# iorx74m register map
Registers are 32-bit, access not given, no defined reset value unless marked. A register's access mark holds for its fields unless they carry their own. Addresses are absolute; registers are grouped by the start of their names; [hi:lo] are bit positions; {n}, {i} and the like mark numbered series.

## SFR (part 1 of 10)
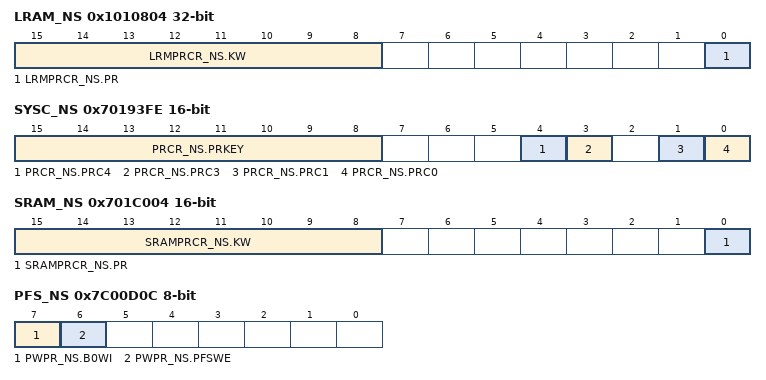
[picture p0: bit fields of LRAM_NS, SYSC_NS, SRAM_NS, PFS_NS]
0x1010804 LRAM_NS
  [15:8] LRMPRCR_NS.KW, [0] LRMPRCR_NS.PR
0x70193FE SYSC_NS 16-bit
  [15:8] PRCR_NS.PRKEY, [4] PRCR_NS.PRC4, [3] PRCR_NS.PRC3, [1] PRCR_NS.PRC1, [0] PRCR_NS.PRC0
0x701C004 SRAM_NS 16-bit
  [15:8] SRAMPRCR_NS.KW, [0] SRAMPRCR_NS.PR
0x7C00D0C PFS_NS 8-bit
  [7] PWPR_NS.B0WI, [6] PWPR_NS.PFSWE
0x81000400 SAU
  [0] AAS.NS
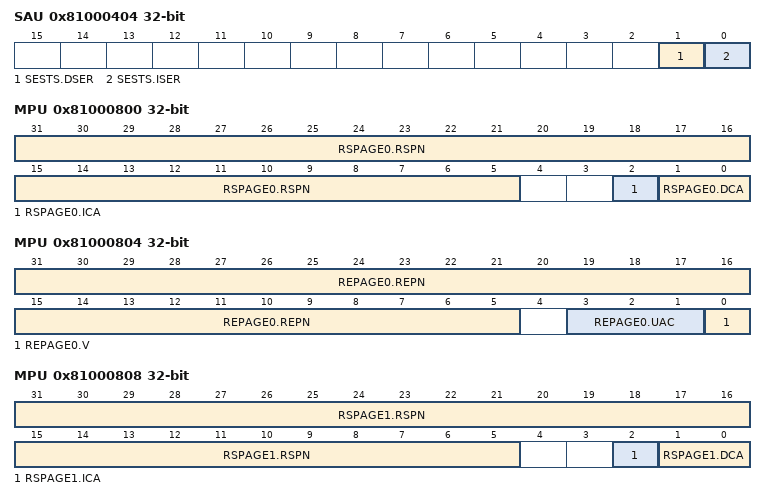
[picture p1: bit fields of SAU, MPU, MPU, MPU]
0x81000404 SAU
  [1] SESTS.DSER, [0] SESTS.ISER
0x81000408 SAU
  [0] SECLR.CLR
0x8100040C SAU
  [31:0] SEA.SEA
0x81000800 MPU
  [31:5] RSPAGE0.RSPN, [2] RSPAGE0.ICA, [1:0] RSPAGE0.DCA
0x81000804 MPU
  [31:5] REPAGE0.REPN, [3:1] REPAGE0.UAC, [0] REPAGE0.V
0x81000808 MPU
  [31:5] RSPAGE1.RSPN, [2] RSPAGE1.ICA, [1:0] RSPAGE1.DCA
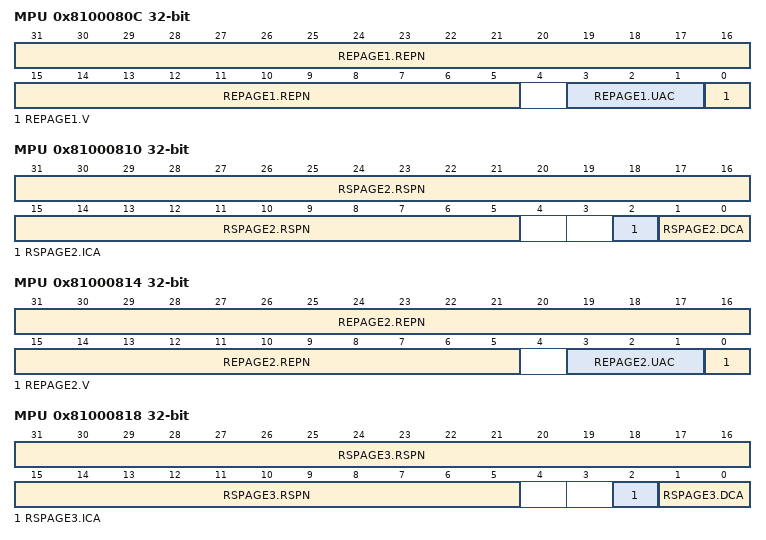
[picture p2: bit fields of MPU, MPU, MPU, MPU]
0x8100080C MPU
  [31:5] REPAGE1.REPN, [3:1] REPAGE1.UAC, [0] REPAGE1.V
0x81000810 MPU
  [31:5] RSPAGE2.RSPN, [2] RSPAGE2.ICA, [1:0] RSPAGE2.DCA
0x81000814 MPU
  [31:5] REPAGE2.REPN, [3:1] REPAGE2.UAC, [0] REPAGE2.V
0x81000818 MPU
  [31:5] RSPAGE3.RSPN, [2] RSPAGE3.ICA, [1:0] RSPAGE3.DCA
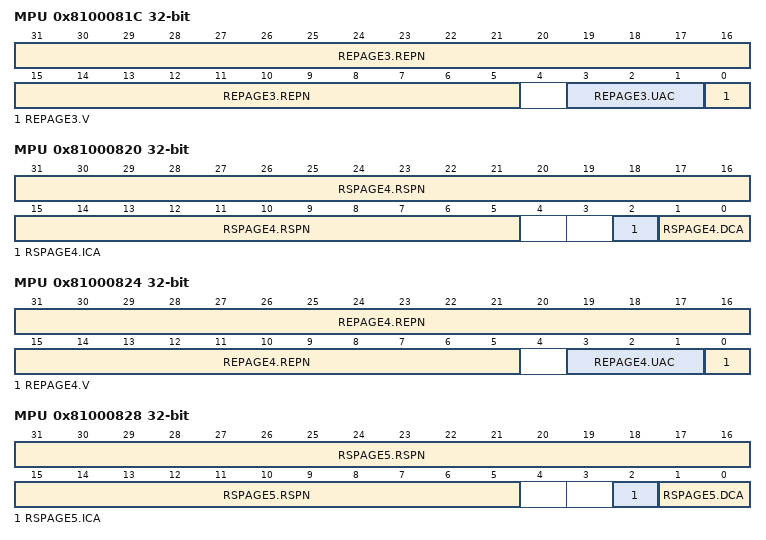
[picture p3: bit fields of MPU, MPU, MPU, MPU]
0x8100081C MPU
  [31:5] REPAGE3.REPN, [3:1] REPAGE3.UAC, [0] REPAGE3.V
0x81000820 MPU
  [31:5] RSPAGE4.RSPN, [2] RSPAGE4.ICA, [1:0] RSPAGE4.DCA
0x81000824 MPU
  [31:5] REPAGE4.REPN, [3:1] REPAGE4.UAC, [0] REPAGE4.V
0x81000828 MPU
  [31:5] RSPAGE5.RSPN, [2] RSPAGE5.ICA, [1:0] RSPAGE5.DCA
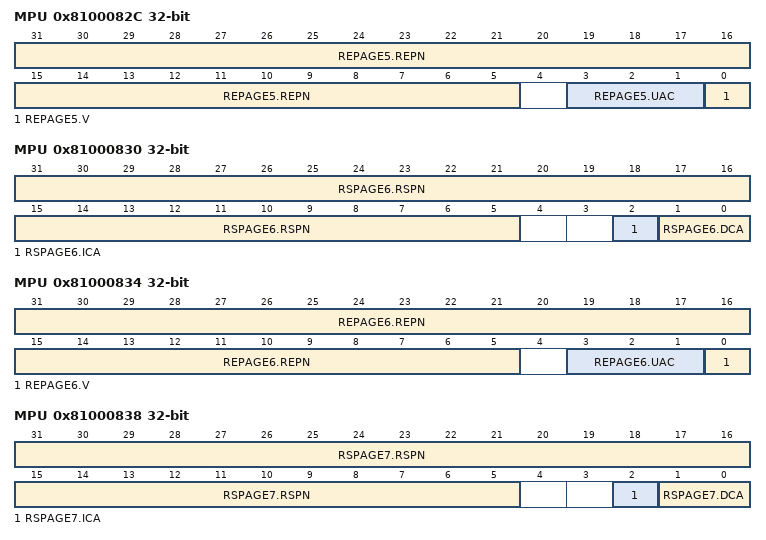
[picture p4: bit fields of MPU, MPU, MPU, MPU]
0x8100082C MPU
  [31:5] REPAGE5.REPN, [3:1] REPAGE5.UAC, [0] REPAGE5.V
0x81000830 MPU
  [31:5] RSPAGE6.RSPN, [2] RSPAGE6.ICA, [1:0] RSPAGE6.DCA
0x81000834 MPU
  [31:5] REPAGE6.REPN, [3:1] REPAGE6.UAC, [0] REPAGE6.V
0x81000838 MPU
  [31:5] RSPAGE7.RSPN, [2] RSPAGE7.ICA, [1:0] RSPAGE7.DCA
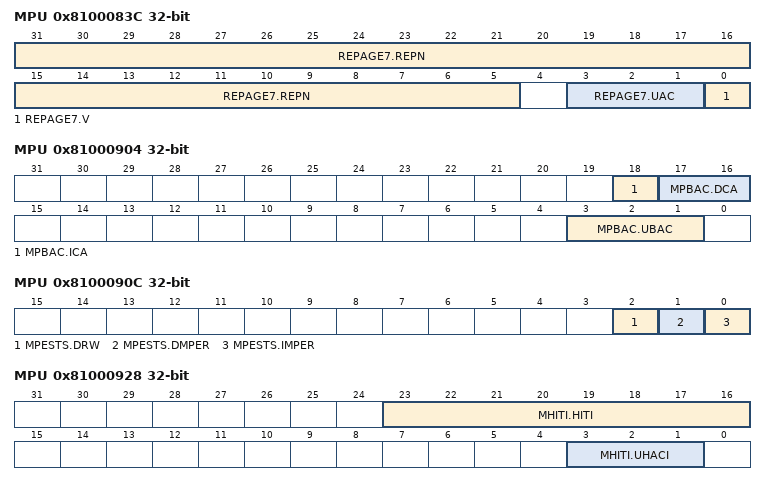
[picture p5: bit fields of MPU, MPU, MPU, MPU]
0x8100083C MPU
  [31:5] REPAGE7.REPN, [3:1] REPAGE7.UAC, [0] REPAGE7.V
0x81000900 MPU
  [0] MPEN.MPEN
0x81000904 MPU
  [18] MPBAC.ICA, [17:16] MPBAC.DCA, [3:1] MPBAC.UBAC
0x81000908 MPU
  [0] MPECLR.CLR
0x8100090C MPU
  [2] MPESTS.DRW, [1] MPESTS.DMPER, [0] MPESTS.IMPER
0x81000914 MPU
  [31:0] MPDEA.DEA
0x81000920 MPU
  [31:0] MPSA.SA
0x81000924 MPU 16-bit
  [0] MPOPS.S
0x81000926 MPU 16-bit
  [0] MPOPI.INV
0x81000928 MPU
  [23:16] MHITI.HITI, [3:1] MHITI.UHACI
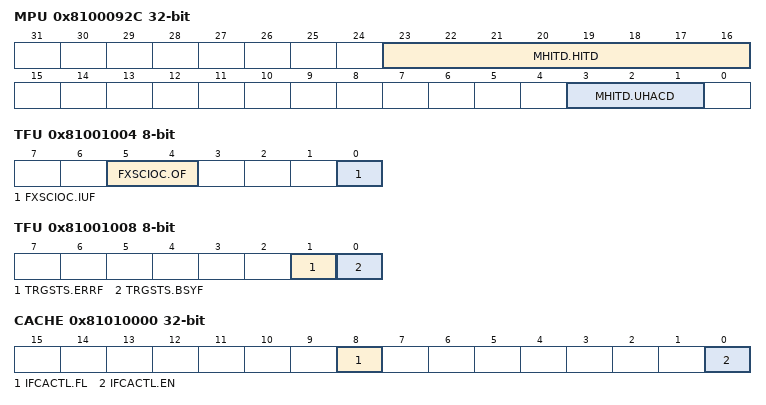
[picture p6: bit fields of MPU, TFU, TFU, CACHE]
0x8100092C MPU
  [23:16] MHITD.HITD, [3:1] MHITD.UHACD
0x81001004 TFU 8-bit
  [5:4] FXSCIOC.OF, [0] FXSCIOC.IUF
0x81001005 TFU 8-bit
  [4] FXATIOC.OUF
0x81001008 TFU 8-bit
  [1] TRGSTS.ERRF, [0] TRGSTS.BSYF
0x81010000 CACHE
  [8] IFCACTL.FL, [0] IFCACTL.EN
0x81010004 CACHE
  [0] IFCAFCT.FL
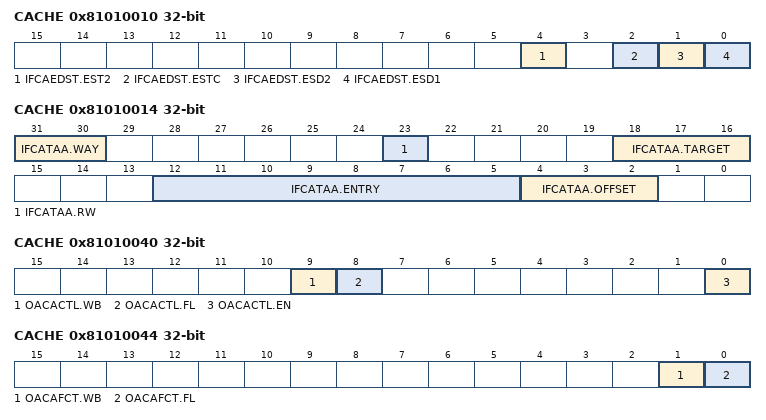
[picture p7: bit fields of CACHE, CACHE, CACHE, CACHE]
0x81010010 CACHE
  [4] IFCAEDST.EST2, [2] IFCAEDST.ESTC, [1] IFCAEDST.ESD2, [0] IFCAEDST.ESD1
0x81010014 CACHE
  [31:30] IFCATAA.WAY, [23] IFCATAA.RW, [18:16] IFCATAA.TARGET, [12:5] IFCATAA.ENTRY, [4:2] IFCATAA.OFFSET
0x81010018 CACHE
  [31:13] IFCATAD_TAG.TAG, [1] IFCATAD_TAG.V, [31:0] IFCATAD_DATA.DATA, [6:0] IFCATAD_ECC.ECC, [4:0] IFCATAD_LRU.LRU, [6:0] IFCATAD_TAGECC.TAGECC
0x81010040 CACHE
  [9] OACACTL.WB, [8] OACACTL.FL, [0] OACACTL.EN
0x81010044 CACHE
  [1] OACAFCT.WB, [0] OACAFCT.FL
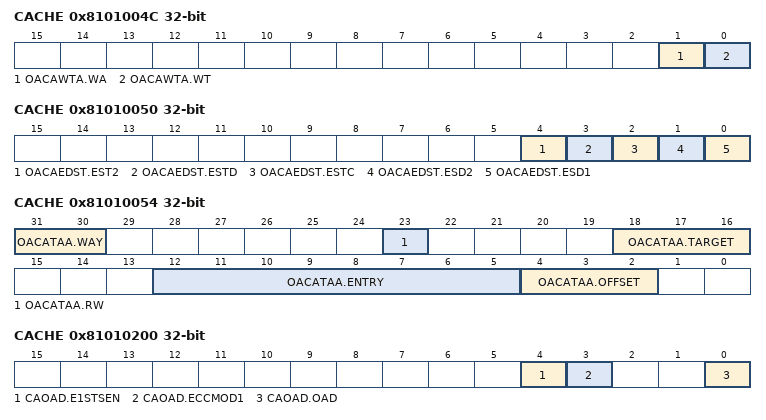
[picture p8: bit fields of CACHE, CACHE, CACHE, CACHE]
0x8101004C CACHE
  [1] OACAWTA.WA, [0] OACAWTA.WT
0x81010050 CACHE
  [4] OACAEDST.EST2, [3] OACAEDST.ESTD, [2] OACAEDST.ESTC, [1] OACAEDST.ESD2, [0] OACAEDST.ESD1
0x81010054 CACHE
  [31:30] OACATAA.WAY, [23] OACATAA.RW, [18:16] OACATAA.TARGET, [12:5] OACATAA.ENTRY, [4:2] OACATAA.OFFSET
0x81010058 CACHE
  [31:13] OACATAD_TAG.TAG, [1] OACATAD_TAG.V, [31:0] OACATAD_DATA.DATA, [6:0] OACATAD_ECC.ECC, [4:0] OACATAD_LRU.LRU, [0] OACATAD_TAG.D, [6:0] OACATAD_TAGECC.TAGECC
0x81010200 CACHE
  [4] CAOAD.E1STSEN, [3] CAOAD.ECCMOD1, [0] CAOAD.OAD
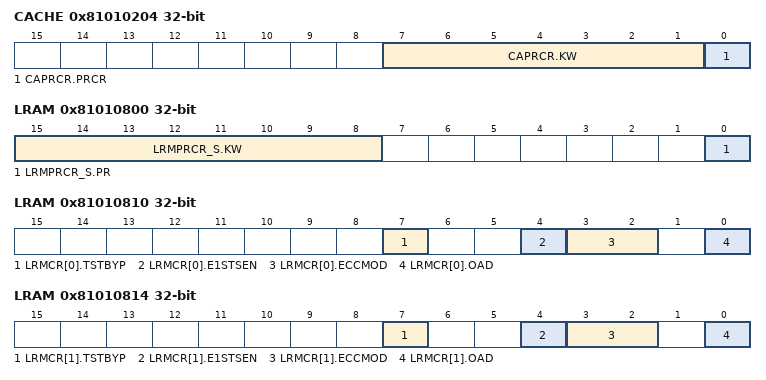
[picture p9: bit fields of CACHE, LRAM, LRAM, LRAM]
0x81010204 CACHE
  [7:1] CAPRCR.KW, [0] CAPRCR.PRCR
0x81010800 LRAM
  [15:8] LRMPRCR_S.KW, [0] LRMPRCR_S.PR
0x81010810 LRAM
  [7] LRMCR[0].TSTBYP, [4] LRMCR[0].E1STSEN, [3:2] LRMCR[0].ECCMOD, [0] LRMCR[0].OAD
0x81010814 LRAM
  [7] LRMCR[1].TSTBYP, [4] LRMCR[1].E1STSEN, [3:2] LRMCR[1].ECCMOD, [0] LRMCR[1].OAD
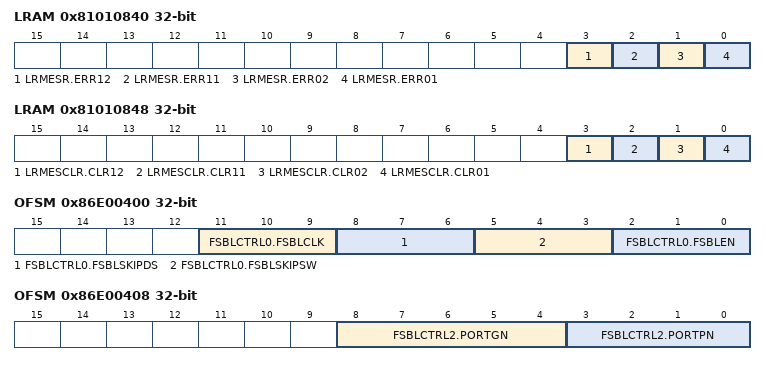
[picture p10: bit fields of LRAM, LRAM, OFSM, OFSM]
0x81010840 LRAM
  [3] LRMESR.ERR12, [2] LRMESR.ERR11, [1] LRMESR.ERR02, [0] LRMESR.ERR01
0x81010848 LRAM
  [3] LRMESCLR.CLR12, [2] LRMESCLR.CLR11, [1] LRMESCLR.CLR02, [0] LRMESCLR.CLR01
0x81010850 LRAM
  [16:2] LRMEAR01.EAR
0x81010854 LRAM
  [16:2] LRMEAR02.EAR
0x81010858 LRAM
  [16:2] LRMEAR11.EAR
0x8101085C LRAM
  [16:2] LRMEAR12.EAR
0x86C2E850 OFSM
  [2:0] DUALSEL.BANKMD
0x86C2E870 OFSM
  [31:30] SAS.BTSIZE
0x86C2E874 OFSM
  [31] SAS2.BTFLG
0x86C2E9B0 OFSM
  [2:0] BANKSEL_SEC.BANKSWP
0x86C2E9C0 OFSM
  [0] BLSEL_SEC.BLSWAREA
0x86C2E9E0 OFSM
  [2:0] BANKSEL_SEL.BANKSWP_SEL
0x86C2E9F0 OFSM
  [0] BLSEL_SEL.BLSWAREA_SEL
0x86E00400 OFSM
  [11:9] FSBLCTRL0.FSBLCLK, [8:6] FSBLCTRL0.FSBLSKIPDS, [5:3] FSBLCTRL0.FSBLSKIPSW, [2:0] FSBLCTRL0.FSBLEN
0x86E00404 OFSM
  [1:0] FSBLCTRL1.FSBLEXMD
0x86E00408 OFSM
  [8:4] FSBLCTRL2.PORTGN, [3:0] FSBLCTRL2.PORTPN
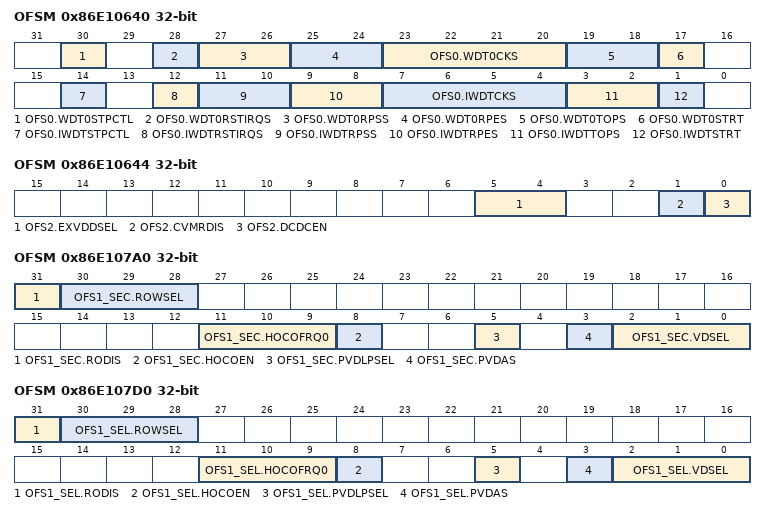
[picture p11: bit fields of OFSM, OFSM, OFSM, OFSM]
0x86E10640 OFSM
  [30] OFS0.WDT0STPCTL, [28] OFS0.WDT0RSTIRQS, [27:26] OFS0.WDT0RPSS, [25:24] OFS0.WDT0RPES, [23:20] OFS0.WDT0CKS, [19:18] OFS0.WDT0TOPS, [17] OFS0.WDT0STRT, [14] OFS0.IWDTSTPCTL, [12] OFS0.IWDTRSTIRQS, [11:10] OFS0.IWDTRPSS, [9:8] OFS0.IWDTRPES, [7:4] OFS0.IWDTCKS, [3:2] OFS0.IWDTTOPS, [1] OFS0.IWDTSTRT
0x86E10644 OFSM
  [5:4] OFS2.EXVDDSEL, [1] OFS2.CVMRDIS, [0] OFS2.DCDCEN
0x86E1064C OFSM
  [2:0] MDE.MDE
0x86E107A0 OFSM
  [31] OFS1_SEC.RODIS, [30:28] OFS1_SEC.ROWSEL, [11:9] OFS1_SEC.HOCOFRQ0, [8] OFS1_SEC.HOCOEN, [5] OFS1_SEC.PVDLPSEL, [3] OFS1_SEC.PVDAS, [2:0] OFS1_SEC.VDSEL
0x86E107D0 OFSM
  [31] OFS1_SEL.RODIS, [30:28] OFS1_SEL.ROWSEL, [11:9] OFS1_SEL.HOCOFRQ0, [8] OFS1_SEL.HOCOEN, [5] OFS1_SEL.PVDLPSEL, [3] OFS1_SEL.PVDAS, [2:0] OFS1_SEL.VDSEL
0x86E30E10 OFSM
  [3:0] REVOKE.REVOKE
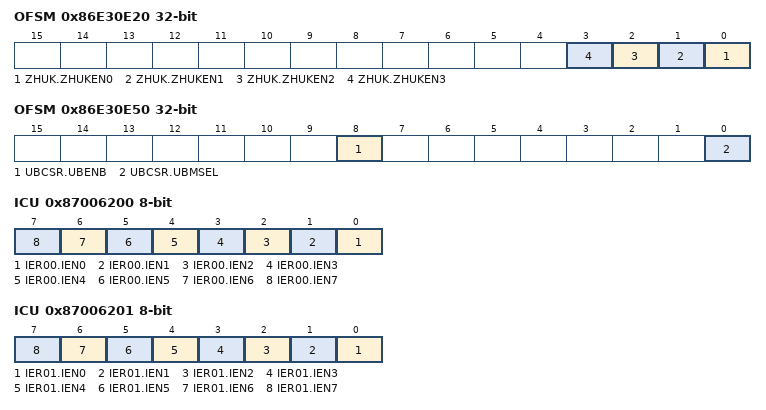
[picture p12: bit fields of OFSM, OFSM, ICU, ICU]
0x86E30E20 OFSM
  [n] ZHUK.ZHUKEN{n} (n=0..3)
0x86E30E30 OFSM
  [17:16] ARCCS.CNF_ARCNS
0x86E30E50 OFSM
  [8] UBCSR.UBENB, [0] UBCSR.UBMSEL
0x86F41D00 OFSM
  [31:0] ARC_SEC0.ARC_SEC
0x86F41D04 OFSM
  [31:0] ARC_SEC1.ARC_SEC
0x86F41E00 OFSM
  [31:0] ARC_NSEC0.ARC_NSEC0
0x86F41E04 OFSM
  [31:0] ARC_NSEC1.ARC_NSEC1
0x86F41E08 OFSM
  [31:0] ARC_NSEC2.ARC_NSEC2
0x86F41E0C OFSM
  [31:0] ARC_NSEC3.ARC_NSEC3
0x86F41E10 OFSM
  [31:0] ARC_NSEC4.ARC_NSEC4
0x86F41E14 OFSM
  [31:0] ARC_NSEC5.ARC_NSEC5
0x86F41E18 OFSM
  [31:0] ARC_NSEC6.ARC_NSEC6
0x86F41E1C OFSM
  [31:0] ARC_NSEC7.ARC_NSEC7
0x86F41F00 OFSM
  [31:0] ARC_OEMBL0.ARC_OEMBL
0x86F41F04 OFSM
  [31:0] ARC_OEMBL1.ARC_OEMBL
0x87006000 ICU 8-bit
  [0] IR[0].IR
0x87006001 ICU 8-bit
  [0] IR[1].IR
0x87006002 ICU 8-bit
  [0] IR[2].IR
0x87006003 ICU 8-bit
  [0] IR[3].IR
0x87006004 ICU 8-bit
  [0] IR[4].IR
0x87006005 ICU 8-bit
  [0] IR[5].IR
0x87006006 ICU 8-bit
  [0] IR[6].IR
0x87006007 ICU 8-bit
  [0] IR[7].IR
0x87006008 ICU 8-bit
  [0] IR[8].IR
0x87006009 ICU 8-bit
  [0] IR[9].IR
0x8700600A ICU 8-bit
  [0] IR[10].IR
0x8700600B ICU 8-bit
  [0] IR[11].IR
0x8700600C ICU 8-bit
  [0] IR[12].IR
0x8700600D ICU 8-bit
  [0] IR[13].IR
0x8700600E ICU 8-bit
  [0] IR[14].IR
0x8700600F ICU 8-bit
  [0] IR[15].IR
0x87006010 ICU 8-bit
  [0] IR[16](BSC,BUSERR).IR
0x87006011 ICU 8-bit
  [0] IR[17](ICU,GROUP_SIL0).IR
0x87006012 ICU 8-bit
  [0] IR[18](ICU,GROUP_IL0).IR
0x87006013 ICU 8-bit
  [0] IR[19].IR
0x87006014 ICU 8-bit
  [0] IR[20].IR
0x87006015 ICU 8-bit
  [0] IR[21].IR
0x87006016 ICU 8-bit
  [0] IR[22].IR
0x87006017 ICU 8-bit
  [0] IR[23].IR
0x87006018 ICU 8-bit
  [0] IR[24].IR
0x87006019 ICU 8-bit
  [0] IR[25].IR
0x8700601A ICU 8-bit
  [0] IR[26](ICU,SWINT2).IR
0x8700601B ICU 8-bit
  [0] IR[27](ICU,SWINT).IR
0x8700601C ICU 8-bit
  [0] IR[28](CMT0,CMI0).IR
0x8700601D ICU 8-bit
  [0] IR[29](CMT1,CMI1).IR
0x8700601E ICU 8-bit
  [0] IR[30](CMTW0,CMWI0).IR
0x8700601F ICU 8-bit
  [0] IR[31](CMTW1,CMWI1).IR
0x87006020 ICU 8-bit
  [0] IR[32](MRAM,MRAM_ENDOFPE).IR
0x87006021 ICU 8-bit
  [0] IR[33](MRAM,MRAM_MRCWR).IR
0x87006022 ICU 8-bit
  [0] IR[34].IR
0x87006023 ICU 8-bit
  [0] IR[35].IR
0x87006024 ICU 8-bit
  [0] IR[36].IR
0x87006025 ICU 8-bit
  [0] IR[37].IR
0x87006026 ICU 8-bit
  [0] IR[38].IR
0x87006027 ICU 8-bit
  [0] IR[39].IR
0x87006028 ICU 8-bit
  [0] IR[40].IR
0x87006029 ICU 8-bit
  [0] IR[41].IR
0x8700602A ICU 8-bit
  [0] IR[42].IR
0x8700602B ICU 8-bit
  [0] IR[43].IR
0x8700602C ICU 8-bit
  [0] IR[44].IR
0x8700602D ICU 8-bit
  [0] IR[45].IR
0x8700602E ICU 8-bit
  [0] IR[46].IR
0x8700602F ICU 8-bit
  [0] IR[47].IR
0x87006030 ICU 8-bit
  [0] IR[48].IR
0x87006031 ICU 8-bit
  [0] IR[49].IR
0x87006032 ICU 8-bit
  [0] IR[50].IR
0x87006033 ICU 8-bit
  [0] IR[51].IR
0x87006034 ICU 8-bit
  [0] IR[52].IR
0x87006035 ICU 8-bit
  [0] IR[53].IR
0x87006036 ICU 8-bit
  [0] IR[54].IR
0x87006037 ICU 8-bit
  [0] IR[55].IR
0x87006038 ICU 8-bit
  [0] IR[56].IR
0x87006039 ICU 8-bit
  [0] IR[57].IR
0x8700603A ICU 8-bit
  [0] IR[58].IR
0x8700603B ICU 8-bit
  [0] IR[59].IR
0x8700603C ICU 8-bit
  [0] IR[60].IR
0x8700603D ICU 8-bit
  [0] IR[61].IR
0x8700603E ICU 8-bit
  [0] IR[62].IR
0x8700603F ICU 8-bit
  [0] IR[63].IR
0x87006040 ICU 8-bit
  [0] IR[64](ICU,IRQ0).IR
0x87006041 ICU 8-bit
  [0] IR[65](ICU,IRQ1).IR
0x87006042 ICU 8-bit
  [0] IR[66](ICU,IRQ2).IR
0x87006043 ICU 8-bit
  [0] IR[67](ICU,IRQ3).IR
0x87006044 ICU 8-bit
  [0] IR[68](ICU,IRQ4).IR
0x87006045 ICU 8-bit
  [0] IR[69](ICU,IRQ5).IR
0x87006046 ICU 8-bit
  [0] IR[70](ICU,IRQ6).IR
0x87006047 ICU 8-bit
  [0] IR[71](ICU,IRQ7).IR
0x87006048 ICU 8-bit
  [0] IR[72](ICU,IRQ8).IR
0x87006049 ICU 8-bit
  [0] IR[73](ICU,IRQ9).IR
0x8700604A ICU 8-bit
  [0] IR[74](ICU,IRQ10).IR
0x8700604B ICU 8-bit
  [0] IR[75](ICU,IRQ11).IR
0x8700604C ICU 8-bit
  [0] IR[76](ICU,IRQ12).IR
0x8700604D ICU 8-bit
  [0] IR[77](ICU,IRQ13).IR
0x8700604E ICU 8-bit
  [0] IR[78](ICU,IRQ14).IR
0x8700604F ICU 8-bit
  [0] IR[79](ICU,IRQ15).IR
0x87006050 ICU 8-bit
  [0] IR[80](RI3C0,I3C_WU0).IR
0x87006051 ICU 8-bit
  [0] IR[81](RIICHS1,WUI1).IR
0x87006052 ICU 8-bit
  [0] IR[82](RIICHS2,WUI2).IR
0x87006053 ICU 8-bit
  [0] IR[83](VBAT,VBAT_TADI).IR
0x87006054 ICU 8-bit
  [0] IR[84](PDM,PDM_SDET).IR
0x87006055 ICU 8-bit
  [0] IR[85](OST,OST).IR
0x87006056 ICU 8-bit
  [0] IR[86].IR
0x87006057 ICU 8-bit
  [0] IR[87].IR
0x87006058 ICU 8-bit
  [0] IR[88](PVD1,PVD1).IR
0x87006059 ICU 8-bit
  [0] IR[89](PVD2,PVD2).IR
0x8700605A ICU 8-bit
  [0] IR[90](USB0,USBR0).IR
0x8700605B ICU 8-bit
  [0] IR[91].IR
0x8700605C ICU 8-bit
  [0] IR[92](RTC,ALM).IR
0x8700605D ICU 8-bit
  [0] IR[93](RTC,PRD).IR
0x8700605E ICU 8-bit
  [0] IR[94](USBHS,USBHSR).IR
0x8700605F ICU 8-bit
  [0] IR[95](IWDT,IWUNI).IR
0x87006060 ICU 8-bit
  [0] IR[96](WDT,WUNI).IR
0x87006061 ICU 8-bit
  [0] IR[97].IR
0x87006062 ICU 8-bit
  [0] IR[98].IR
0x87006063 ICU 8-bit
  [0] IR[99].IR
0x87006064 ICU 8-bit
  [0] IR[100].IR
0x87006065 ICU 8-bit
  [0] IR[101].IR
0x87006066 ICU 8-bit
  [0] IR[102](ICU,GROUP_SBL0).IR
0x87006067 ICU 8-bit
  [0] IR[103](ICU,GROUP_SBL1).IR
0x87006068 ICU 8-bit
  [0] IR[104](ICU,GROUP_SAL0).IR
0x87006069 ICU 8-bit
  [0] IR[105](ICU,GROUP_SAL1).IR
0x8700606A ICU 8-bit
  [0] IR[106](ICU,GROUP_SAL2).IR
0x8700606B ICU 8-bit
  [0] IR[107](ICU,GROUP_SAL3).IR
0x8700606C ICU 8-bit
  [0] IR[108](ICU,GROUP_SAL4).IR
0x8700606D ICU 8-bit
  [0] IR[109](ICU,GROUP_SAL5).IR
0x8700606E ICU 8-bit
  [0] IR[110].IR
0x8700606F ICU 8-bit
  [0] IR[111](ICU,GROUP_BL0).IR
0x87006070 ICU 8-bit
  [0] IR[112](ICU,GROUP_BL1).IR
0x87006071 ICU 8-bit
  [0] IR[113](ICU,GROUP_AL0).IR
0x87006072 ICU 8-bit
  [0] IR[114](ICU,GROUP_AL1).IR
0x87006073 ICU 8-bit
  [0] IR[115](ICU,GROUP_AL2).IR
0x87006074 ICU 8-bit
  [0] IR[116](ICU,GROUP_AL3).IR
0x87006075 ICU 8-bit
  [0] IR[117](ICU,GROUP_AL4).IR
0x87006076 ICU 8-bit
  [0] IR[118](ICU,GROUP_AL5).IR
0x87006077 ICU 8-bit
  [0] IR[119].IR
0x87006078 ICU 8-bit
  [0] IR[120](DMAC,DMAC0I).IR
0x87006079 ICU 8-bit
  [0] IR[121](DMAC,DMAC1I).IR
0x8700607A ICU 8-bit
  [0] IR[122](DMAC,DMAC2I).IR
0x8700607B ICU 8-bit
  [0] IR[123](DMAC,DMAC3I).IR
0x8700607C ICU 8-bit
  [0] IR[124](DMAC,DMAC74I).IR
0x8700607D ICU 8-bit
  [0] IR[125](OST,OSTDI).IR
0x8700607E ICU 8-bit
  [0] IR[126](EXDMAC,EXDMAC0I).IR
0x8700607F ICU 8-bit
  [0] IR[127](EXDMAC,EXDMAC1I).IR
0x87006080 ICU 8-bit
  [0] IR[128](PERIAB,INTAB128).IR
0x87006081 ICU 8-bit
  [0] IR[129](PERIAB,INTAB129).IR
0x87006082 ICU 8-bit
  [0] IR[130](PERIAB,INTAB130).IR
0x87006083 ICU 8-bit
  [0] IR[131](PERIAB,INTAB131).IR
0x87006084 ICU 8-bit
  [0] IR[132](PERIAB,INTAB132).IR
0x87006085 ICU 8-bit
  [0] IR[133](PERIAB,INTAB133).IR
0x87006086 ICU 8-bit
  [0] IR[134](PERIAB,INTAB134).IR
0x87006087 ICU 8-bit
  [0] IR[135](PERIAB,INTAB135).IR
0x87006088 ICU 8-bit
  [0] IR[136](PERIAB,INTAB136).IR
0x87006089 ICU 8-bit
  [0] IR[137](PERIAB,INTAB137).IR
0x8700608A ICU 8-bit
  [0] IR[138](PERIAB,INTAB138).IR
0x8700608B ICU 8-bit
  [0] IR[139](PERIAB,INTAB139).IR
0x8700608C ICU 8-bit
  [0] IR[140](PERIAB,INTAB140).IR
0x8700608D ICU 8-bit
  [0] IR[141](PERIAB,INTAB141).IR
0x8700608E ICU 8-bit
  [0] IR[142](PERIAB,INTAB142).IR
0x8700608F ICU 8-bit
  [0] IR[143](PERIAB,INTAB143).IR
0x87006090 ICU 8-bit
  [0] IR[144](PERIAB,INTAB144).IR
0x87006091 ICU 8-bit
  [0] IR[145](PERIAB,INTAB145).IR
0x87006092 ICU 8-bit
  [0] IR[146](PERIAB,INTAB146).IR
0x87006093 ICU 8-bit
  [0] IR[147](PERIAB,INTAB147).IR
0x87006094 ICU 8-bit
  [0] IR[148](PERIAB,INTAB148).IR
0x87006095 ICU 8-bit
  [0] IR[149](PERIAB,INTAB149).IR
0x87006096 ICU 8-bit
  [0] IR[150](PERIAB,INTAB150).IR
0x87006097 ICU 8-bit
  [0] IR[151](PERIAB,INTAB151).IR
0x87006098 ICU 8-bit
  [0] IR[152](PERIAB,INTAB152).IR
0x87006099 ICU 8-bit
  [0] IR[153](PERIAB,INTAB153).IR
0x8700609A ICU 8-bit
  [0] IR[154](PERIAB,INTAB154).IR
0x8700609B ICU 8-bit
  [0] IR[155](PERIAB,INTAB155).IR
0x8700609C ICU 8-bit
  [0] IR[156](PERIAB,INTAB156).IR
0x8700609D ICU 8-bit
  [0] IR[157](PERIAB,INTAB157).IR
0x8700609E ICU 8-bit
  [0] IR[158](PERIAB,INTAB158).IR
0x8700609F ICU 8-bit
  [0] IR[159](PERIAB,INTAB159).IR
0x870060A0 ICU 8-bit
  [0] IR[160](PERIAB,INTAB160).IR
0x870060A1 ICU 8-bit
  [0] IR[161](PERIAB,INTAB161).IR
0x870060A2 ICU 8-bit
  [0] IR[162](PERIAB,INTAB162).IR
0x870060A3 ICU 8-bit
  [0] IR[163](PERIAB,INTAB163).IR
0x870060A4 ICU 8-bit
  [0] IR[164](PERIAB,INTAB164).IR
0x870060A5 ICU 8-bit
  [0] IR[165](PERIAB,INTAB165).IR
0x870060A6 ICU 8-bit
  [0] IR[166](PERIAB,INTAB166).IR
0x870060A7 ICU 8-bit
  [0] IR[167](PERIAB,INTAB167).IR
0x870060A8 ICU 8-bit
  [0] IR[168](PERIAB,INTAB168).IR
0x870060A9 ICU 8-bit
  [0] IR[169](PERIAB,INTAB169).IR
0x870060AA ICU 8-bit
  [0] IR[170](PERIAB,INTAB170).IR
0x870060AB ICU 8-bit
  [0] IR[171](PERIAB,INTAB171).IR
0x870060AC ICU 8-bit
  [0] IR[172](PERIAB,INTAB172).IR
0x870060AD ICU 8-bit
  [0] IR[173](PERIAB,INTAB173).IR
0x870060AE ICU 8-bit
  [0] IR[174](PERIAB,INTAB174).IR
0x870060AF ICU 8-bit
  [0] IR[175](PERIAB,INTAB175).IR
0x870060B0 ICU 8-bit
  [0] IR[176](PERIAB,INTAB176).IR
0x870060B1 ICU 8-bit
  [0] IR[177](PERIAB,INTAB177).IR
0x870060B2 ICU 8-bit
  [0] IR[178](PERIAB,INTAB178).IR
0x870060B3 ICU 8-bit
  [0] IR[179](PERIAB,INTAB179).IR
0x870060B4 ICU 8-bit
  [0] IR[180](PERIAB,INTAB180).IR
0x870060B5 ICU 8-bit
  [0] IR[181](PERIAB,INTAB181).IR
0x870060B6 ICU 8-bit
  [0] IR[182](PERIAB,INTAB182).IR
0x870060B7 ICU 8-bit
  [0] IR[183](PERIAB,INTAB183).IR
0x870060B8 ICU 8-bit
  [0] IR[184](PERIAB,INTAB184).IR
0x870060B9 ICU 8-bit
  [0] IR[185](PERIAB,INTAB185).IR
0x870060BA ICU 8-bit
  [0] IR[186](PERIAB,INTAB186).IR
0x870060BB ICU 8-bit
  [0] IR[187](PERIAB,INTAB187).IR
0x870060BC ICU 8-bit
  [0] IR[188](PERIAB,INTAB188).IR
0x870060BD ICU 8-bit
  [0] IR[189](PERIAB,INTAB189).IR
0x870060BE ICU 8-bit
  [0] IR[190](PERIAB,INTAB190).IR
0x870060BF ICU 8-bit
  [0] IR[191](PERIAB,INTAB191).IR
0x870060C0 ICU 8-bit
  [0] IR[192](PERIAB,INTAB192).IR
0x870060C1 ICU 8-bit
  [0] IR[193](PERIAB,INTAB193).IR
0x870060C2 ICU 8-bit
  [0] IR[194](PERIAB,INTAB194).IR
0x870060C3 ICU 8-bit
  [0] IR[195](PERIAB,INTAB195).IR
0x870060C4 ICU 8-bit
  [0] IR[196](PERIAB,INTAB196).IR
0x870060C5 ICU 8-bit
  [0] IR[197](PERIAB,INTAB197).IR
0x870060C6 ICU 8-bit
  [0] IR[198](PERIAB,INTAB198).IR
0x870060C7 ICU 8-bit
  [0] IR[199](PERIAB,INTAB199).IR
0x870060C8 ICU 8-bit
  [0] IR[200](PERIAB,INTAB200).IR
0x870060C9 ICU 8-bit
  [0] IR[201](PERIAB,INTAB201).IR
0x870060CA ICU 8-bit
  [0] IR[202](PERIAB,INTAB202).IR
0x870060CB ICU 8-bit
  [0] IR[203](PERIAB,INTAB203).IR
0x870060CC ICU 8-bit
  [0] IR[204](PERIAB,INTAB204).IR
0x870060CD ICU 8-bit
  [0] IR[205](PERIAB,INTAB205).IR
0x870060CE ICU 8-bit
  [0] IR[206](PERIAB,INTAB206).IR
0x870060CF ICU 8-bit
  [0] IR[207](PERIAB,INTAB207).IR
0x870060D0 ICU 8-bit
  [0] IR[208](PERIAB,INTAB208).IR
0x870060D1 ICU 8-bit
  [0] IR[209](PERIAB,INTAB209).IR
0x870060D2 ICU 8-bit
  [0] IR[210](PERIAB,INTAB210).IR
0x870060D3 ICU 8-bit
  [0] IR[211](PERIAB,INTAB211).IR
0x870060D4 ICU 8-bit
  [0] IR[212](PERIAB,INTAB212).IR
0x870060D5 ICU 8-bit
  [0] IR[213](PERIAB,INTAB213).IR
0x870060D6 ICU 8-bit
  [0] IR[214](PERIAB,INTAB214).IR
0x870060D7 ICU 8-bit
  [0] IR[215](PERIAB,INTAB215).IR
0x870060D8 ICU 8-bit
  [0] IR[216](PERIAB,INTAB216).IR
0x870060D9 ICU 8-bit
  [0] IR[217](PERIAB,INTAB217).IR
0x870060DA ICU 8-bit
  [0] IR[218](PERIAB,INTAB218).IR
0x870060DB ICU 8-bit
  [0] IR[219](PERIAB,INTAB219).IR
0x870060DC ICU 8-bit
  [0] IR[220](PERIAB,INTAB220).IR
0x870060DD ICU 8-bit
  [0] IR[221](PERIAB,INTAB221).IR
0x870060DE ICU 8-bit
  [0] IR[222](PERIAB,INTAB222).IR
0x870060DF ICU 8-bit
  [0] IR[223](PERIAB,INTAB223).IR
0x870060E0 ICU 8-bit
  [0] IR[224](PERIAB,INTAB224).IR
0x870060E1 ICU 8-bit
  [0] IR[225](PERIAB,INTAB225).IR
0x870060E2 ICU 8-bit
  [0] IR[226](PERIAB,INTAB226).IR
0x870060E3 ICU 8-bit
  [0] IR[227](PERIAB,INTAB227).IR
0x870060E4 ICU 8-bit
  [0] IR[228](PERIAB,INTAB228).IR
0x870060E5 ICU 8-bit
  [0] IR[229](PERIAB,INTAB229).IR
0x870060E6 ICU 8-bit
  [0] IR[230](PERIAB,INTAB230).IR
0x870060E7 ICU 8-bit
  [0] IR[231](PERIAB,INTAB231).IR
0x870060E8 ICU 8-bit
  [0] IR[232](PERIAB,INTAB232).IR
0x870060E9 ICU 8-bit
  [0] IR[233](PERIAB,INTAB233).IR
0x870060EA ICU 8-bit
  [0] IR[234](PERIAB,INTAB234).IR
0x870060EB ICU 8-bit
  [0] IR[235](PERIAB,INTAB235).IR
0x870060EC ICU 8-bit
  [0] IR[236](PERIAB,INTAB236).IR
0x870060ED ICU 8-bit
  [0] IR[237](PERIAB,INTAB237).IR
0x870060EE ICU 8-bit
  [0] IR[238](PERIAB,INTAB238).IR
0x870060EF ICU 8-bit
  [0] IR[239](PERIAB,INTAB239).IR
0x870060F0 ICU 8-bit
  [0] IR[240](PERIAB,INTAB240).IR
0x870060F1 ICU 8-bit
  [0] IR[241](PERIAB,INTAB241).IR
0x870060F2 ICU 8-bit
  [0] IR[242](PERIAB,INTAB242).IR
0x870060F3 ICU 8-bit
  [0] IR[243](PERIAB,INTAB243).IR
0x870060F4 ICU 8-bit
  [0] IR[244](PERIAB,INTAB244).IR
0x870060F5 ICU 8-bit
  [0] IR[245](PERIAB,INTAB245).IR
0x870060F6 ICU 8-bit
  [0] IR[246](PERIAB,INTAB246).IR
0x870060F7 ICU 8-bit
  [0] IR[247](PERIAB,INTAB247).IR
0x870060F8 ICU 8-bit
  [0] IR[248](PERIAB,INTAB248).IR
0x870060F9 ICU 8-bit
  [0] IR[249](PERIAB,INTAB249).IR
0x870060FA ICU 8-bit
  [0] IR[250](PERIAB,INTAB250).IR
0x870060FB ICU 8-bit
  [0] IR[251](PERIAB,INTAB251).IR
0x870060FC ICU 8-bit
  [0] IR[252](PERIAB,INTAB252).IR
0x870060FD ICU 8-bit
  [0] IR[253](PERIAB,INTAB253).IR
0x870060FE ICU 8-bit
  [0] IR[254](PERIAB,INTAB254).IR
0x870060FF ICU 8-bit
  [0] IR[255](PERIAB,INTAB255).IR
0x87006100 ICU 8-bit
  [0] DTCER[0].DTCE
0x87006101 ICU 8-bit
  [0] DTCER[1].DTCE
0x87006102 ICU 8-bit
  [0] DTCER[2].DTCE
0x87006103 ICU 8-bit
  [0] DTCER[3].DTCE
0x87006104 ICU 8-bit
  [0] DTCER[4].DTCE
0x87006105 ICU 8-bit
  [0] DTCER[5].DTCE
0x87006106 ICU 8-bit
  [0] DTCER[6].DTCE
0x87006107 ICU 8-bit
  [0] DTCER[7].DTCE
0x87006108 ICU 8-bit
  [0] DTCER[8].DTCE
0x87006109 ICU 8-bit
  [0] DTCER[9].DTCE
0x8700610A ICU 8-bit
  [0] DTCER[10].DTCE
0x8700610B ICU 8-bit
  [0] DTCER[11].DTCE
0x8700610C ICU 8-bit
  [0] DTCER[12].DTCE
0x8700610D ICU 8-bit
  [0] DTCER[13].DTCE
0x8700610E ICU 8-bit
  [0] DTCER[14].DTCE
0x8700610F ICU 8-bit
  [0] DTCER[15].DTCE
0x87006110 ICU 8-bit
  [0] DTCER[16](BSC,BUSERR).DTCE
0x87006111 ICU 8-bit
  [0] DTCER[17](ICU,GROUP_SIL0).DTCE
0x87006112 ICU 8-bit
  [0] DTCER[18](ICU,GROUP_IL0).DTCE
0x87006113 ICU 8-bit
  [0] DTCER[19].DTCE
0x87006114 ICU 8-bit
  [0] DTCER[20].DTCE
0x87006115 ICU 8-bit
  [0] DTCER[21].DTCE
0x87006116 ICU 8-bit
  [0] DTCER[22].DTCE
0x87006117 ICU 8-bit
  [0] DTCER[23].DTCE
0x87006118 ICU 8-bit
  [0] DTCER[24].DTCE
0x87006119 ICU 8-bit
  [0] DTCER[25].DTCE
0x8700611A ICU 8-bit
  [0] DTCER[26](ICU,SWINT2).DTCE
0x8700611B ICU 8-bit
  [0] DTCER[27](ICU,SWINT).DTCE
0x8700611C ICU 8-bit
  [0] DTCER[28](CMT0,CMI0).DTCE
0x8700611D ICU 8-bit
  [0] DTCER[29](CMT1,CMI1).DTCE
0x8700611E ICU 8-bit
  [0] DTCER[30](CMTW0,CMWI0).DTCE
0x8700611F ICU 8-bit
  [0] DTCER[31](CMTW1,CMWI1).DTCE
0x87006120 ICU 8-bit
  [0] DTCER[32](MRAM,MRAM_ENDOFPE).DTCE
0x87006121 ICU 8-bit
  [0] DTCER[33](MRAM,MRAM_MRCWR).DTCE
0x87006122 ICU 8-bit
  [0] DTCER[34].DTCE
0x87006123 ICU 8-bit
  [0] DTCER[35].DTCE
0x87006124 ICU 8-bit
  [0] DTCER[36].DTCE
0x87006125 ICU 8-bit
  [0] DTCER[37].DTCE
0x87006126 ICU 8-bit
  [0] DTCER[38].DTCE
0x87006127 ICU 8-bit
  [0] DTCER[39].DTCE
0x87006128 ICU 8-bit
  [0] DTCER[40].DTCE
0x87006129 ICU 8-bit
  [0] DTCER[41].DTCE
0x8700612A ICU 8-bit
  [0] DTCER[42].DTCE
0x8700612B ICU 8-bit
  [0] DTCER[43].DTCE
0x8700612C ICU 8-bit
  [0] DTCER[44].DTCE
0x8700612D ICU 8-bit
  [0] DTCER[45].DTCE
0x8700612E ICU 8-bit
  [0] DTCER[46].DTCE
0x8700612F ICU 8-bit
  [0] DTCER[47].DTCE
0x87006130 ICU 8-bit
  [0] DTCER[48].DTCE
0x87006131 ICU 8-bit
  [0] DTCER[49].DTCE
0x87006132 ICU 8-bit
  [0] DTCER[50].DTCE
0x87006133 ICU 8-bit
  [0] DTCER[51].DTCE
0x87006134 ICU 8-bit
  [0] DTCER[52].DTCE
0x87006135 ICU 8-bit
  [0] DTCER[53].DTCE
0x87006136 ICU 8-bit
  [0] DTCER[54].DTCE
0x87006137 ICU 8-bit
  [0] DTCER[55].DTCE
0x87006138 ICU 8-bit
  [0] DTCER[56].DTCE
0x87006139 ICU 8-bit
  [0] DTCER[57].DTCE
0x8700613A ICU 8-bit
  [0] DTCER[58].DTCE
0x8700613B ICU 8-bit
  [0] DTCER[59].DTCE
0x8700613C ICU 8-bit
  [0] DTCER[60].DTCE
0x8700613D ICU 8-bit
  [0] DTCER[61].DTCE
0x8700613E ICU 8-bit
  [0] DTCER[62].DTCE
0x8700613F ICU 8-bit
  [0] DTCER[63].DTCE
0x87006140 ICU 8-bit
  [0] DTCER[64](ICU,IRQ0).DTCE
0x87006141 ICU 8-bit
  [0] DTCER[65](ICU,IRQ1).DTCE
0x87006142 ICU 8-bit
  [0] DTCER[66](ICU,IRQ2).DTCE
0x87006143 ICU 8-bit
  [0] DTCER[67](ICU,IRQ3).DTCE
0x87006144 ICU 8-bit
  [0] DTCER[68](ICU,IRQ4).DTCE
0x87006145 ICU 8-bit
  [0] DTCER[69](ICU,IRQ5).DTCE
0x87006146 ICU 8-bit
  [0] DTCER[70](ICU,IRQ6).DTCE
0x87006147 ICU 8-bit
  [0] DTCER[71](ICU,IRQ7).DTCE
0x87006148 ICU 8-bit
  [0] DTCER[72](ICU,IRQ8).DTCE
0x87006149 ICU 8-bit
  [0] DTCER[73](ICU,IRQ9).DTCE
0x8700614A ICU 8-bit
  [0] DTCER[74](ICU,IRQ10).DTCE
0x8700614B ICU 8-bit
  [0] DTCER[75](ICU,IRQ11).DTCE
0x8700614C ICU 8-bit
  [0] DTCER[76](ICU,IRQ12).DTCE
0x8700614D ICU 8-bit
  [0] DTCER[77](ICU,IRQ13).DTCE
0x8700614E ICU 8-bit
  [0] DTCER[78](ICU,IRQ14).DTCE
0x8700614F ICU 8-bit
  [0] DTCER[79](ICU,IRQ15).DTCE
0x87006150 ICU 8-bit
  [0] DTCER[80](RI3C0,I3C_WU0).DTCE
0x87006151 ICU 8-bit
  [0] DTCER[81](RIICHS1,WUI1).DTCE
0x87006152 ICU 8-bit
  [0] DTCER[82](RIICHS2,WUI2).DTCE
0x87006153 ICU 8-bit
  [0] DTCER[83](VBAT,VBAT_TADI).DTCE
0x87006154 ICU 8-bit
  [0] DTCER[84](PDM,PDM_SDET).DTCE
0x87006155 ICU 8-bit
  [0] DTCER[85](OST,OST).DTCE
0x87006156 ICU 8-bit
  [0] DTCER[86].DTCE
0x87006157 ICU 8-bit
  [0] DTCER[87].DTCE
0x87006158 ICU 8-bit
  [0] DTCER[88](PVD1,PVD1).DTCE
0x87006159 ICU 8-bit
  [0] DTCER[89](PVD2,PVD2).DTCE
0x8700615A ICU 8-bit
  [0] DTCER[90](USB0,USBR0).DTCE
0x8700615B ICU 8-bit
  [0] DTCER[91].DTCE
0x8700615C ICU 8-bit
  [0] DTCER[92](RTC,ALM).DTCE
0x8700615D ICU 8-bit
  [0] DTCER[93](RTC,PRD).DTCE
0x8700615E ICU 8-bit
  [0] DTCER[94](USBHS,USBHSR).DTCE
0x8700615F ICU 8-bit
  [0] DTCER[95](IWDT,IWUNI).DTCE
0x87006160 ICU 8-bit
  [0] DTCER[96](WDT,WUNI).DTCE
0x87006161 ICU 8-bit
  [0] DTCER[97].DTCE
0x87006162 ICU 8-bit
  [0] DTCER[98].DTCE
0x87006163 ICU 8-bit
  [0] DTCER[99].DTCE
0x87006164 ICU 8-bit
  [0] DTCER[100].DTCE
0x87006165 ICU 8-bit
  [0] DTCER[101].DTCE
0x87006166 ICU 8-bit
  [0] DTCER[102](ICU,GROUP_SBL0).DTCE
0x87006167 ICU 8-bit
  [0] DTCER[103](ICU,GROUP_SBL1).DTCE
0x87006168 ICU 8-bit
  [0] DTCER[104](ICU,GROUP_SAL0).DTCE
0x87006169 ICU 8-bit
  [0] DTCER[105](ICU,GROUP_SAL1).DTCE
0x8700616A ICU 8-bit
  [0] DTCER[106](ICU,GROUP_SAL2).DTCE
0x8700616B ICU 8-bit
  [0] DTCER[107](ICU,GROUP_SAL3).DTCE
0x8700616C ICU 8-bit
  [0] DTCER[108](ICU,GROUP_SAL4).DTCE
0x8700616D ICU 8-bit
  [0] DTCER[109](ICU,GROUP_SAL5).DTCE
0x8700616E ICU 8-bit
  [0] DTCER[110].DTCE
0x8700616F ICU 8-bit
  [0] DTCER[111](ICU,GROUP_BL0).DTCE
0x87006170 ICU 8-bit
  [0] DTCER[112](ICU,GROUP_BL1).DTCE
0x87006171 ICU 8-bit
  [0] DTCER[113](ICU,GROUP_AL0).DTCE
0x87006172 ICU 8-bit
  [0] DTCER[114](ICU,GROUP_AL1).DTCE
0x87006173 ICU 8-bit
  [0] DTCER[115](ICU,GROUP_AL2).DTCE
0x87006174 ICU 8-bit
  [0] DTCER[116](ICU,GROUP_AL3).DTCE
0x87006175 ICU 8-bit
  [0] DTCER[117](ICU,GROUP_AL4).DTCE
0x87006176 ICU 8-bit
  [0] DTCER[118](ICU,GROUP_AL5).DTCE
0x87006177 ICU 8-bit
  [0] DTCER[119].DTCE
0x87006178 ICU 8-bit
  [0] DTCER[120](DMAC,DMAC0I).DTCE
0x87006179 ICU 8-bit
  [0] DTCER[121](DMAC,DMAC1I).DTCE
0x8700617A ICU 8-bit
  [0] DTCER[122](DMAC,DMAC2I).DTCE
0x8700617B ICU 8-bit
  [0] DTCER[123](DMAC,DMAC3I).DTCE
0x8700617C ICU 8-bit
  [0] DTCER[124](DMAC,DMAC74I).DTCE
0x8700617D ICU 8-bit
  [0] DTCER[125](OST,OSTDI).DTCE
0x8700617E ICU 8-bit
  [0] DTCER[126](EXDMAC,EXDMAC0I).DTCE
0x8700617F ICU 8-bit
  [0] DTCER[127](EXDMAC,EXDMAC1I).DTCE
0x87006180 ICU 8-bit
  [0] DTCER[128](PERIAB,INTAB128).DTCE
0x87006181 ICU 8-bit
  [0] DTCER[129](PERIAB,INTAB129).DTCE
0x87006182 ICU 8-bit
  [0] DTCER[130](PERIAB,INTAB130).DTCE
0x87006183 ICU 8-bit
  [0] DTCER[131](PERIAB,INTAB131).DTCE
0x87006184 ICU 8-bit
  [0] DTCER[132](PERIAB,INTAB132).DTCE
0x87006185 ICU 8-bit
  [0] DTCER[133](PERIAB,INTAB133).DTCE
0x87006186 ICU 8-bit
  [0] DTCER[134](PERIAB,INTAB134).DTCE
0x87006187 ICU 8-bit
  [0] DTCER[135](PERIAB,INTAB135).DTCE
0x87006188 ICU 8-bit
  [0] DTCER[136](PERIAB,INTAB136).DTCE
0x87006189 ICU 8-bit
  [0] DTCER[137](PERIAB,INTAB137).DTCE
0x8700618A ICU 8-bit
  [0] DTCER[138](PERIAB,INTAB138).DTCE
0x8700618B ICU 8-bit
  [0] DTCER[139](PERIAB,INTAB139).DTCE
0x8700618C ICU 8-bit
  [0] DTCER[140](PERIAB,INTAB140).DTCE
0x8700618D ICU 8-bit
  [0] DTCER[141](PERIAB,INTAB141).DTCE
0x8700618E ICU 8-bit
  [0] DTCER[142](PERIAB,INTAB142).DTCE
0x8700618F ICU 8-bit
  [0] DTCER[143](PERIAB,INTAB143).DTCE
0x87006190 ICU 8-bit
  [0] DTCER[144](PERIAB,INTAB144).DTCE
0x87006191 ICU 8-bit
  [0] DTCER[145](PERIAB,INTAB145).DTCE
0x87006192 ICU 8-bit
  [0] DTCER[146](PERIAB,INTAB146).DTCE
0x87006193 ICU 8-bit
  [0] DTCER[147](PERIAB,INTAB147).DTCE
0x87006194 ICU 8-bit
  [0] DTCER[148](PERIAB,INTAB148).DTCE
0x87006195 ICU 8-bit
  [0] DTCER[149](PERIAB,INTAB149).DTCE
0x87006196 ICU 8-bit
  [0] DTCER[150](PERIAB,INTAB150).DTCE
0x87006197 ICU 8-bit
  [0] DTCER[151](PERIAB,INTAB151).DTCE
0x87006198 ICU 8-bit
  [0] DTCER[152](PERIAB,INTAB152).DTCE
0x87006199 ICU 8-bit
  [0] DTCER[153](PERIAB,INTAB153).DTCE
0x8700619A ICU 8-bit
  [0] DTCER[154](PERIAB,INTAB154).DTCE
0x8700619B ICU 8-bit
  [0] DTCER[155](PERIAB,INTAB155).DTCE
0x8700619C ICU 8-bit
  [0] DTCER[156](PERIAB,INTAB156).DTCE
0x8700619D ICU 8-bit
  [0] DTCER[157](PERIAB,INTAB157).DTCE
0x8700619E ICU 8-bit
  [0] DTCER[158](PERIAB,INTAB158).DTCE
0x8700619F ICU 8-bit
  [0] DTCER[159](PERIAB,INTAB159).DTCE
0x870061A0 ICU 8-bit
  [0] DTCER[160](PERIAB,INTAB160).DTCE
0x870061A1 ICU 8-bit
  [0] DTCER[161](PERIAB,INTAB161).DTCE
0x870061A2 ICU 8-bit
  [0] DTCER[162](PERIAB,INTAB162).DTCE
0x870061A3 ICU 8-bit
  [0] DTCER[163](PERIAB,INTAB163).DTCE
0x870061A4 ICU 8-bit
  [0] DTCER[164](PERIAB,INTAB164).DTCE
0x870061A5 ICU 8-bit
  [0] DTCER[165](PERIAB,INTAB165).DTCE
0x870061A6 ICU 8-bit
  [0] DTCER[166](PERIAB,INTAB166).DTCE
0x870061A7 ICU 8-bit
  [0] DTCER[167](PERIAB,INTAB167).DTCE
0x870061A8 ICU 8-bit
  [0] DTCER[168](PERIAB,INTAB168).DTCE
0x870061A9 ICU 8-bit
  [0] DTCER[169](PERIAB,INTAB169).DTCE
0x870061AA ICU 8-bit
  [0] DTCER[170](PERIAB,INTAB170).DTCE
0x870061AB ICU 8-bit
  [0] DTCER[171](PERIAB,INTAB171).DTCE
0x870061AC ICU 8-bit
  [0] DTCER[172](PERIAB,INTAB172).DTCE
0x870061AD ICU 8-bit
  [0] DTCER[173](PERIAB,INTAB173).DTCE
0x870061AE ICU 8-bit
  [0] DTCER[174](PERIAB,INTAB174).DTCE
0x870061AF ICU 8-bit
  [0] DTCER[175](PERIAB,INTAB175).DTCE
0x870061B0 ICU 8-bit
  [0] DTCER[176](PERIAB,INTAB176).DTCE
0x870061B1 ICU 8-bit
  [0] DTCER[177](PERIAB,INTAB177).DTCE
0x870061B2 ICU 8-bit
  [0] DTCER[178](PERIAB,INTAB178).DTCE
0x870061B3 ICU 8-bit
  [0] DTCER[179](PERIAB,INTAB179).DTCE
0x870061B4 ICU 8-bit
  [0] DTCER[180](PERIAB,INTAB180).DTCE
0x870061B5 ICU 8-bit
  [0] DTCER[181](PERIAB,INTAB181).DTCE
0x870061B6 ICU 8-bit
  [0] DTCER[182](PERIAB,INTAB182).DTCE
0x870061B7 ICU 8-bit
  [0] DTCER[183](PERIAB,INTAB183).DTCE
0x870061B8 ICU 8-bit
  [0] DTCER[184](PERIAB,INTAB184).DTCE
0x870061B9 ICU 8-bit
  [0] DTCER[185](PERIAB,INTAB185).DTCE
0x870061BA ICU 8-bit
  [0] DTCER[186](PERIAB,INTAB186).DTCE
0x870061BB ICU 8-bit
  [0] DTCER[187](PERIAB,INTAB187).DTCE
0x870061BC ICU 8-bit
  [0] DTCER[188](PERIAB,INTAB188).DTCE
0x870061BD ICU 8-bit
  [0] DTCER[189](PERIAB,INTAB189).DTCE
0x870061BE ICU 8-bit
  [0] DTCER[190](PERIAB,INTAB190).DTCE
0x870061BF ICU 8-bit
  [0] DTCER[191](PERIAB,INTAB191).DTCE
0x870061C0 ICU 8-bit
  [0] DTCER[192](PERIAB,INTAB192).DTCE
0x870061C1 ICU 8-bit
  [0] DTCER[193](PERIAB,INTAB193).DTCE
0x870061C2 ICU 8-bit
  [0] DTCER[194](PERIAB,INTAB194).DTCE
0x870061C3 ICU 8-bit
  [0] DTCER[195](PERIAB,INTAB195).DTCE
0x870061C4 ICU 8-bit
  [0] DTCER[196](PERIAB,INTAB196).DTCE
0x870061C5 ICU 8-bit
  [0] DTCER[197](PERIAB,INTAB197).DTCE
0x870061C6 ICU 8-bit
  [0] DTCER[198](PERIAB,INTAB198).DTCE
0x870061C7 ICU 8-bit
  [0] DTCER[199](PERIAB,INTAB199).DTCE
0x870061C8 ICU 8-bit
  [0] DTCER[200](PERIAB,INTAB200).DTCE
0x870061C9 ICU 8-bit
  [0] DTCER[201](PERIAB,INTAB201).DTCE
0x870061CA ICU 8-bit
  [0] DTCER[202](PERIAB,INTAB202).DTCE
0x870061CB ICU 8-bit
  [0] DTCER[203](PERIAB,INTAB203).DTCE
0x870061CC ICU 8-bit
  [0] DTCER[204](PERIAB,INTAB204).DTCE
0x870061CD ICU 8-bit
  [0] DTCER[205](PERIAB,INTAB205).DTCE
0x870061CE ICU 8-bit
  [0] DTCER[206](PERIAB,INTAB206).DTCE
0x870061CF ICU 8-bit
  [0] DTCER[207](PERIAB,INTAB207).DTCE
0x870061D0 ICU 8-bit
  [0] DTCER[208](PERIAB,INTAB208).DTCE
0x870061D1 ICU 8-bit
  [0] DTCER[209](PERIAB,INTAB209).DTCE
0x870061D2 ICU 8-bit
  [0] DTCER[210](PERIAB,INTAB210).DTCE
0x870061D3 ICU 8-bit
  [0] DTCER[211](PERIAB,INTAB211).DTCE
0x870061D4 ICU 8-bit
  [0] DTCER[212](PERIAB,INTAB212).DTCE
0x870061D5 ICU 8-bit
  [0] DTCER[213](PERIAB,INTAB213).DTCE
0x870061D6 ICU 8-bit
  [0] DTCER[214](PERIAB,INTAB214).DTCE
0x870061D7 ICU 8-bit
  [0] DTCER[215](PERIAB,INTAB215).DTCE
0x870061D8 ICU 8-bit
  [0] DTCER[216](PERIAB,INTAB216).DTCE
0x870061D9 ICU 8-bit
  [0] DTCER[217](PERIAB,INTAB217).DTCE
0x870061DA ICU 8-bit
  [0] DTCER[218](PERIAB,INTAB218).DTCE
0x870061DB ICU 8-bit
  [0] DTCER[219](PERIAB,INTAB219).DTCE
0x870061DC ICU 8-bit
  [0] DTCER[220](PERIAB,INTAB220).DTCE
0x870061DD ICU 8-bit
  [0] DTCER[221](PERIAB,INTAB221).DTCE
0x870061DE ICU 8-bit
  [0] DTCER[222](PERIAB,INTAB222).DTCE
0x870061DF ICU 8-bit
  [0] DTCER[223](PERIAB,INTAB223).DTCE
0x870061E0 ICU 8-bit
  [0] DTCER[224](PERIAB,INTAB224).DTCE
0x870061E1 ICU 8-bit
  [0] DTCER[225](PERIAB,INTAB225).DTCE
0x870061E2 ICU 8-bit
  [0] DTCER[226](PERIAB,INTAB226).DTCE
0x870061E3 ICU 8-bit
  [0] DTCER[227](PERIAB,INTAB227).DTCE
0x870061E4 ICU 8-bit
  [0] DTCER[228](PERIAB,INTAB228).DTCE
0x870061E5 ICU 8-bit
  [0] DTCER[229](PERIAB,INTAB229).DTCE
0x870061E6 ICU 8-bit
  [0] DTCER[230](PERIAB,INTAB230).DTCE
0x870061E7 ICU 8-bit
  [0] DTCER[231](PERIAB,INTAB231).DTCE
0x870061E8 ICU 8-bit
  [0] DTCER[232](PERIAB,INTAB232).DTCE
0x870061E9 ICU 8-bit
  [0] DTCER[233](PERIAB,INTAB233).DTCE
0x870061EA ICU 8-bit
  [0] DTCER[234](PERIAB,INTAB234).DTCE
0x870061EB ICU 8-bit
  [0] DTCER[235](PERIAB,INTAB235).DTCE
0x870061EC ICU 8-bit
  [0] DTCER[236](PERIAB,INTAB236).DTCE
0x870061ED ICU 8-bit
  [0] DTCER[237](PERIAB,INTAB237).DTCE
0x870061EE ICU 8-bit
  [0] DTCER[238](PERIAB,INTAB238).DTCE
0x870061EF ICU 8-bit
  [0] DTCER[239](PERIAB,INTAB239).DTCE
0x870061F0 ICU 8-bit
  [0] DTCER[240](PERIAB,INTAB240).DTCE
0x870061F1 ICU 8-bit
  [0] DTCER[241](PERIAB,INTAB241).DTCE
0x870061F2 ICU 8-bit
  [0] DTCER[242](PERIAB,INTAB242).DTCE
0x870061F3 ICU 8-bit
  [0] DTCER[243](PERIAB,INTAB243).DTCE
0x870061F4 ICU 8-bit
  [0] DTCER[244](PERIAB,INTAB244).DTCE
0x870061F5 ICU 8-bit
  [0] DTCER[245](PERIAB,INTAB245).DTCE
0x870061F6 ICU 8-bit
  [0] DTCER[246](PERIAB,INTAB246).DTCE
0x870061F7 ICU 8-bit
  [0] DTCER[247](PERIAB,INTAB247).DTCE
0x870061F8 ICU 8-bit
  [0] DTCER[248](PERIAB,INTAB248).DTCE
0x870061F9 ICU 8-bit
  [0] DTCER[249](PERIAB,INTAB249).DTCE
0x870061FA ICU 8-bit
  [0] DTCER[250](PERIAB,INTAB250).DTCE
0x870061FB ICU 8-bit
  [0] DTCER[251](PERIAB,INTAB251).DTCE
0x870061FC ICU 8-bit
  [0] DTCER[252](PERIAB,INTAB252).DTCE
0x870061FD ICU 8-bit
  [0] DTCER[253](PERIAB,INTAB253).DTCE
0x870061FE ICU 8-bit
  [0] DTCER[254](PERIAB,INTAB254).DTCE
0x870061FF ICU 8-bit
  [0] DTCER[255](PERIAB,INTAB255).DTCE
0x87006200 ICU 8-bit
  [n] IER00.IEN{n} (n=0..7)
0x87006201 ICU 8-bit
  [n] IER01.IEN{n} (n=0..7)
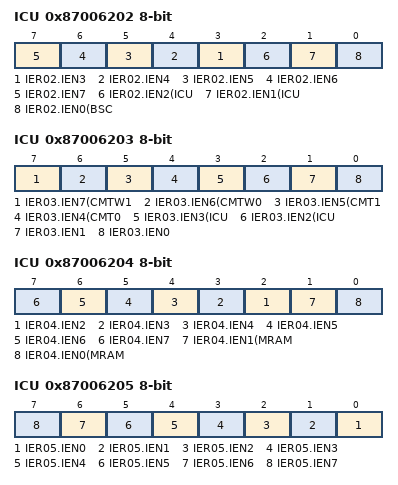
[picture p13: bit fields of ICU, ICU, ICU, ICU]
0x87006202 ICU 8-bit
  [n] IER02.IEN{n} (n=3..7), [2] IER02.IEN2(ICU,GROUP_IL0), [1] IER02.IEN1(ICU,GROUP_SIL0), [0] IER02.IEN0(BSC,BUSERR)
0x87006203 ICU 8-bit
  [7] IER03.IEN7(CMTW1,CMWI1), [6] IER03.IEN6(CMTW0,CMWI0), [5] IER03.IEN5(CMT1,CMI1), [4] IER03.IEN4(CMT0,CMI0), [3] IER03.IEN3(ICU,SWINT), [2] IER03.IEN2(ICU,SWINT2), [1] IER03.IEN1, [0] IER03.IEN0
0x87006204 ICU 8-bit
  [n] IER04.IEN{n} (n=2..7), [1] IER04.IEN1(MRAM,MRAM_MRCWR), [0] IER04.IEN0(MRAM,MRAM_ENDOFPE)
0x87006205 ICU 8-bit
  [n] IER05.IEN{n} (n=0..7)
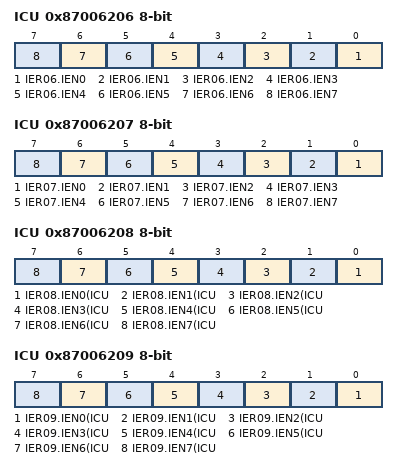
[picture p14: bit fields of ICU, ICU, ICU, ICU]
0x87006206 ICU 8-bit
  [n] IER06.IEN{n} (n=0..7)
0x87006207 ICU 8-bit
  [n] IER07.IEN{n} (n=0..7)
0x87006208 ICU 8-bit
  [n] IER08.IEN{n}(ICU,IRQ{n}) (n=0..7)
0x87006209 ICU 8-bit
  [n] IER09.IEN{n}(ICU,IRQ{n+8}) (n=0..7)
0x8700620A ICU 8-bit
  [7] IER0A.IEN7, [6] IER0A.IEN6, [5] IER0A.IEN5(OST,OST), [4] IER0A.IEN4(PDM,PDM_SDET), [3] IER0A.IEN3(VBAT,VBAT_TADI), [2] IER0A.IEN2(RIICHS2,WUI2), [1] IER0A.IEN1(RIICHS1,WUI1), [0] IER0A.IEN0(RI3C0,I3C_WU0)
0x8700620B ICU 8-bit
  [7] IER0B.IEN7(IWDT,IWUNI), [6] IER0B.IEN6(USBHS,USBHSR), [5] IER0B.IEN5(RTC,PRD), [4] IER0B.IEN4(RTC,ALM), [3] IER0B.IEN3, [2] IER0B.IEN2(USB0,USBR0), [1] IER0B.IEN1(PVD2,PVD2), [0] IER0B.IEN0(PVD1,PVD1)
0x8700620C ICU 8-bit
  [7] IER0C.IEN7(ICU,GROUP_SBL1), [6] IER0C.IEN6(ICU,GROUP_SBL0), [n] IER0C.IEN{n} (n=1..5), [0] IER0C.IEN0(WDT,WUNI)
0x8700620D ICU 8-bit
  [7] IER0D.IEN7(ICU,GROUP_BL0), [6] IER0D.IEN6, [n] IER0D.IEN{n}(ICU,GROUP_SAL{n}) (n=0..5)
0x8700620E ICU 8-bit
  [7] IER0E.IEN7, [n] IER0E.IEN{n}(ICU,GROUP_AL{n-1}) (n=1..6), [0] IER0E.IEN0(ICU,GROUP_BL1)
0x8700620F ICU 8-bit
  [7] IER0F.IEN7(EXDMAC,EXDMAC1I), [6] IER0F.IEN6(EXDMAC,EXDMAC0I), [5] IER0F.IEN5(OST,OSTDI), [4] IER0F.IEN4(DMAC,DMAC74I), [n] IER0F.IEN{n}(DMAC,DMAC{n}I) (n=0..3)
0x87006210 ICU 8-bit
  [n] IER10.IEN{n}(PERIAB,INTAB{n+128}) (n=0..7)
0x87006211 ICU 8-bit
  [n] IER11.IEN{n}(PERIAB,INTAB{n+136}) (n=0..7)
0x87006212 ICU 8-bit
  [n] IER12.IEN{n}(PERIAB,INTAB{n+144}) (n=0..7)
0x87006213 ICU 8-bit
  [n] IER13.IEN{n}(PERIAB,INTAB{n+152}) (n=0..7)
0x87006214 ICU 8-bit
  [n] IER14.IEN{n}(PERIAB,INTAB{n+160}) (n=0..7)
0x87006215 ICU 8-bit
  [n] IER15.IEN{n}(PERIAB,INTAB{n+168}) (n=0..7)
0x87006216 ICU 8-bit
  [n] IER16.IEN{n}(PERIAB,INTAB{n+176}) (n=0..7)
0x87006217 ICU 8-bit
  [n] IER17.IEN{n}(PERIAB,INTAB{n+184}) (n=0..7)
0x87006218 ICU 8-bit
  [n] IER18.IEN{n}(PERIAB,INTAB{n+192}) (n=0..7)
0x87006219 ICU 8-bit
  [n] IER19.IEN{n}(PERIAB,INTAB{n+200}) (n=0..7)
0x8700621A ICU 8-bit
  [n] IER1A.IEN{n}(PERIAB,INTAB{n+208}) (n=0..7)
0x8700621B ICU 8-bit
  [n] IER1B.IEN{n}(PERIAB,INTAB{n+216}) (n=0..7)
0x8700621C ICU 8-bit
  [n] IER1C.IEN{n}(PERIAB,INTAB{n+224}) (n=0..7)
0x8700621D ICU 8-bit
  [n] IER1D.IEN{n}(PERIAB,INTAB{n+232}) (n=0..7)
0x8700621E ICU 8-bit
  [n] IER1E.IEN{n}(PERIAB,INTAB{n+240}) (n=0..7)
0x8700621F ICU 8-bit
  [n] IER1F.IEN{n}(PERIAB,INTAB{n+248}) (n=0..7)
0x870062E0 ICU 8-bit
  [0] SWINTR.SWINT
0x870062E1 ICU 8-bit
  [0] SWINT2R.SWINT2
0x870062F0 ICU 16-bit
  [15] FIR.FIEN, [7:0] FIR.FVCT
0x87006300 ICU 8-bit
  [4:0] IPR[0](BSC,BUSERR).IPR
0x87006301 ICU 8-bit
  [4:0] IPR[1](ICU,GROUP_SIL0).IPR
0x87006302 ICU 8-bit
  [4:0] IPR[2](ICU,GROUP_IL0).IPR
0x87006303 ICU 8-bit
  [4:0] IPR[3](ICU,SWINT).IPR
0x87006304 ICU 8-bit
  [4:0] IPR[4](CMT0,CMI0).IPR
0x87006305 ICU 8-bit
  [4:0] IPR[5](CMT1,CMI1).IPR
0x87006306 ICU 8-bit
  [4:0] IPR[6](CMTW0,CMWI0).IPR
0x87006307 ICU 8-bit
  [4:0] IPR[7](CMTW1,CMWI1).IPR
0x87006308 ICU 8-bit
  [4:0] IPR[8](ICU,SWINT2).IPR
0x87006309 ICU 8-bit
  [4:0] IPR[9].IPR
0x8700630A ICU 8-bit
  [4:0] IPR[10].IPR
0x8700630B ICU 8-bit
  [4:0] IPR[11].IPR
0x8700630C ICU 8-bit
  [4:0] IPR[12].IPR
0x8700630D ICU 8-bit
  [4:0] IPR[13].IPR
0x8700630E ICU 8-bit
  [4:0] IPR[14].IPR
0x8700630F ICU 8-bit
  [4:0] IPR[15].IPR
0x87006310 ICU 8-bit
  [4:0] IPR[16].IPR
0x87006311 ICU 8-bit
  [4:0] IPR[17].IPR
0x87006312 ICU 8-bit
  [4:0] IPR[18].IPR
0x87006313 ICU 8-bit
  [4:0] IPR[19].IPR
0x87006314 ICU 8-bit
  [4:0] IPR[20].IPR
0x87006315 ICU 8-bit
  [4:0] IPR[21].IPR
0x87006316 ICU 8-bit
  [4:0] IPR[22].IPR
0x87006317 ICU 8-bit
  [4:0] IPR[23].IPR
0x87006318 ICU 8-bit
  [4:0] IPR[24].IPR
0x87006319 ICU 8-bit
  [4:0] IPR[25].IPR
0x8700631A ICU 8-bit
  [4:0] IPR[26].IPR
0x8700631B ICU 8-bit
  [4:0] IPR[27].IPR
0x8700631C ICU 8-bit
  [4:0] IPR[28].IPR
0x8700631D ICU 8-bit
  [4:0] IPR[29].IPR
0x8700631E ICU 8-bit
  [4:0] IPR[30].IPR
0x8700631F ICU 8-bit
  [4:0] IPR[31].IPR
0x87006320 ICU 8-bit
  [4:0] IPR[32](MRAM,MRAM_ENDOFPE).IPR
0x87006321 ICU 8-bit
  [4:0] IPR[33](MRAM,MRAM_MRCWR).IPR
0x87006322 ICU 8-bit
  [4:0] IPR[34].IPR
0x87006323 ICU 8-bit
  [4:0] IPR[35].IPR
0x87006324 ICU 8-bit
  [4:0] IPR[36].IPR
0x87006325 ICU 8-bit
  [4:0] IPR[37].IPR
0x87006326 ICU 8-bit
  [4:0] IPR[38].IPR
0x87006327 ICU 8-bit
  [4:0] IPR[39].IPR
0x87006328 ICU 8-bit
  [4:0] IPR[40].IPR
0x87006329 ICU 8-bit
  [4:0] IPR[41].IPR
0x8700632A ICU 8-bit
  [4:0] IPR[42].IPR
0x8700632B ICU 8-bit
  [4:0] IPR[43].IPR
0x8700632C ICU 8-bit
  [4:0] IPR[44].IPR
0x8700632D ICU 8-bit
  [4:0] IPR[45].IPR
0x8700632E ICU 8-bit
  [4:0] IPR[46].IPR
0x8700632F ICU 8-bit
  [4:0] IPR[47].IPR
0x87006330 ICU 8-bit
  [4:0] IPR[48].IPR
0x87006331 ICU 8-bit
  [4:0] IPR[49].IPR
0x87006332 ICU 8-bit
  [4:0] IPR[50].IPR
0x87006333 ICU 8-bit
  [4:0] IPR[51].IPR
0x87006334 ICU 8-bit
  [4:0] IPR[52].IPR
0x87006335 ICU 8-bit
  [4:0] IPR[53].IPR
0x87006336 ICU 8-bit
  [4:0] IPR[54].IPR
0x87006337 ICU 8-bit
  [4:0] IPR[55].IPR
0x87006338 ICU 8-bit
  [4:0] IPR[56].IPR
0x87006339 ICU 8-bit
  [4:0] IPR[57].IPR
0x8700633A ICU 8-bit
  [4:0] IPR[58].IPR
0x8700633B ICU 8-bit
  [4:0] IPR[59].IPR
0x8700633C ICU 8-bit
  [4:0] IPR[60].IPR
0x8700633D ICU 8-bit
  [4:0] IPR[61].IPR
0x8700633E ICU 8-bit
  [4:0] IPR[62].IPR
0x8700633F ICU 8-bit
  [4:0] IPR[63].IPR
0x87006340 ICU 8-bit
  [4:0] IPR[64](ICU,IRQ0).IPR
0x87006341 ICU 8-bit
  [4:0] IPR[65](ICU,IRQ1).IPR
0x87006342 ICU 8-bit
  [4:0] IPR[66](ICU,IRQ2).IPR
0x87006343 ICU 8-bit
  [4:0] IPR[67](ICU,IRQ3).IPR
0x87006344 ICU 8-bit
  [4:0] IPR[68](ICU,IRQ4).IPR
0x87006345 ICU 8-bit
  [4:0] IPR[69](ICU,IRQ5).IPR
0x87006346 ICU 8-bit
  [4:0] IPR[70](ICU,IRQ6).IPR
0x87006347 ICU 8-bit
  [4:0] IPR[71](ICU,IRQ7).IPR
0x87006348 ICU 8-bit
  [4:0] IPR[72](ICU,IRQ8).IPR
0x87006349 ICU 8-bit
  [4:0] IPR[73](ICU,IRQ9).IPR
0x8700634A ICU 8-bit
  [4:0] IPR[74](ICU,IRQ10).IPR
0x8700634B ICU 8-bit
  [4:0] IPR[75](ICU,IRQ11).IPR
0x8700634C ICU 8-bit
  [4:0] IPR[76](ICU,IRQ12).IPR
0x8700634D ICU 8-bit
  [4:0] IPR[77](ICU,IRQ13).IPR
0x8700634E ICU 8-bit
  [4:0] IPR[78](ICU,IRQ14).IPR
0x8700634F ICU 8-bit
  [4:0] IPR[79](ICU,IRQ15).IPR
0x87006350 ICU 8-bit
  [4:0] IPR[80](RI3C0,I3C_WU0).IPR
0x87006351 ICU 8-bit
  [4:0] IPR[81](RIICHS1,WUI1).IPR
0x87006352 ICU 8-bit
  [4:0] IPR[82](RIICHS2,WUI2).IPR
0x87006353 ICU 8-bit
  [4:0] IPR[83](VBAT,VBAT_TADI).IPR
0x87006354 ICU 8-bit
  [4:0] IPR[84](PDM,PDM_SDET).IPR
0x87006355 ICU 8-bit
  [4:0] IPR[85](OST,OST).IPR
0x87006356 ICU 8-bit
  [4:0] IPR[86].IPR
0x87006357 ICU 8-bit
  [4:0] IPR[87].IPR
0x87006358 ICU 8-bit
  [4:0] IPR[88](PVD1,PVD1).IPR
0x87006359 ICU 8-bit
  [4:0] IPR[89](PVD2,PVD2).IPR
0x8700635A ICU 8-bit
  [4:0] IPR[90](USB0,USBR0).IPR
0x8700635B ICU 8-bit
  [4:0] IPR[91].IPR
0x8700635C ICU 8-bit
  [4:0] IPR[92](RTC,ALM).IPR
0x8700635D ICU 8-bit
  [4:0] IPR[93](RTC,PRD).IPR
0x8700635E ICU 8-bit
  [4:0] IPR[94](USBHS,USBHSR).IPR
0x8700635F ICU 8-bit
  [4:0] IPR[95](IWDT,IWUNI).IPR
0x87006360 ICU 8-bit
  [4:0] IPR[96](WDT,WUNI).IPR
0x87006361 ICU 8-bit
  [4:0] IPR[97].IPR
0x87006362 ICU 8-bit
  [4:0] IPR[98].IPR
0x87006363 ICU 8-bit
  [4:0] IPR[99].IPR
0x87006364 ICU 8-bit
  [4:0] IPR[100].IPR
0x87006365 ICU 8-bit
  [4:0] IPR[101].IPR
0x87006366 ICU 8-bit
  [4:0] IPR[102](ICU,GROUP_SBL0).IPR
0x87006367 ICU 8-bit
  [4:0] IPR[103](ICU,GROUP_SBL1).IPR
0x87006368 ICU 8-bit
  [4:0] IPR[104](ICU,GROUP_SAL0).IPR
0x87006369 ICU 8-bit
  [4:0] IPR[105](ICU,GROUP_SAL1).IPR
0x8700636A ICU 8-bit
  [4:0] IPR[106](ICU,GROUP_SAL2).IPR
0x8700636B ICU 8-bit
  [4:0] IPR[107](ICU,GROUP_SAL3).IPR
0x8700636C ICU 8-bit
  [4:0] IPR[108](ICU,GROUP_SAL4).IPR
0x8700636D ICU 8-bit
  [4:0] IPR[109](ICU,GROUP_SAL5).IPR
0x8700636E ICU 8-bit
  [4:0] IPR[110].IPR
0x8700636F ICU 8-bit
  [4:0] IPR[111](ICU,GROUP_BL0).IPR
0x87006370 ICU 8-bit
  [4:0] IPR[112](ICU,GROUP_BL1).IPR
0x87006371 ICU 8-bit
  [4:0] IPR[113](ICU,GROUP_AL0).IPR
0x87006372 ICU 8-bit
  [4:0] IPR[114](ICU,GROUP_AL1).IPR
0x87006373 ICU 8-bit
  [4:0] IPR[115](ICU,GROUP_AL2).IPR
0x87006374 ICU 8-bit
  [4:0] IPR[116](ICU,GROUP_AL3).IPR
0x87006375 ICU 8-bit
  [4:0] IPR[117](ICU,GROUP_AL4).IPR
0x87006376 ICU 8-bit
  [4:0] IPR[118](ICU,GROUP_AL5).IPR
0x87006377 ICU 8-bit
  [4:0] IPR[119].IPR
0x87006378 ICU 8-bit
  [4:0] IPR[120](DMAC,DMAC0I).IPR
0x87006379 ICU 8-bit
  [4:0] IPR[121](DMAC,DMAC1I).IPR
0x8700637A ICU 8-bit
  [4:0] IPR[122](DMAC,DMAC2I).IPR
0x8700637B ICU 8-bit
  [4:0] IPR[123](DMAC,DMAC3I).IPR
0x8700637C ICU 8-bit
  [4:0] IPR[124](DMAC,DMAC74I).IPR
0x8700637D ICU 8-bit
  [4:0] IPR[125](OST,OSTDI).IPR
0x8700637E ICU 8-bit
  [4:0] IPR[126](EXDMAC,EXDMAC0I).IPR
0x8700637F ICU 8-bit
  [4:0] IPR[127](EXDMAC,EXDMAC1I).IPR
0x87006380 ICU 8-bit
  [4:0] IPR[128](PERIAB,INTAB128).IPR
